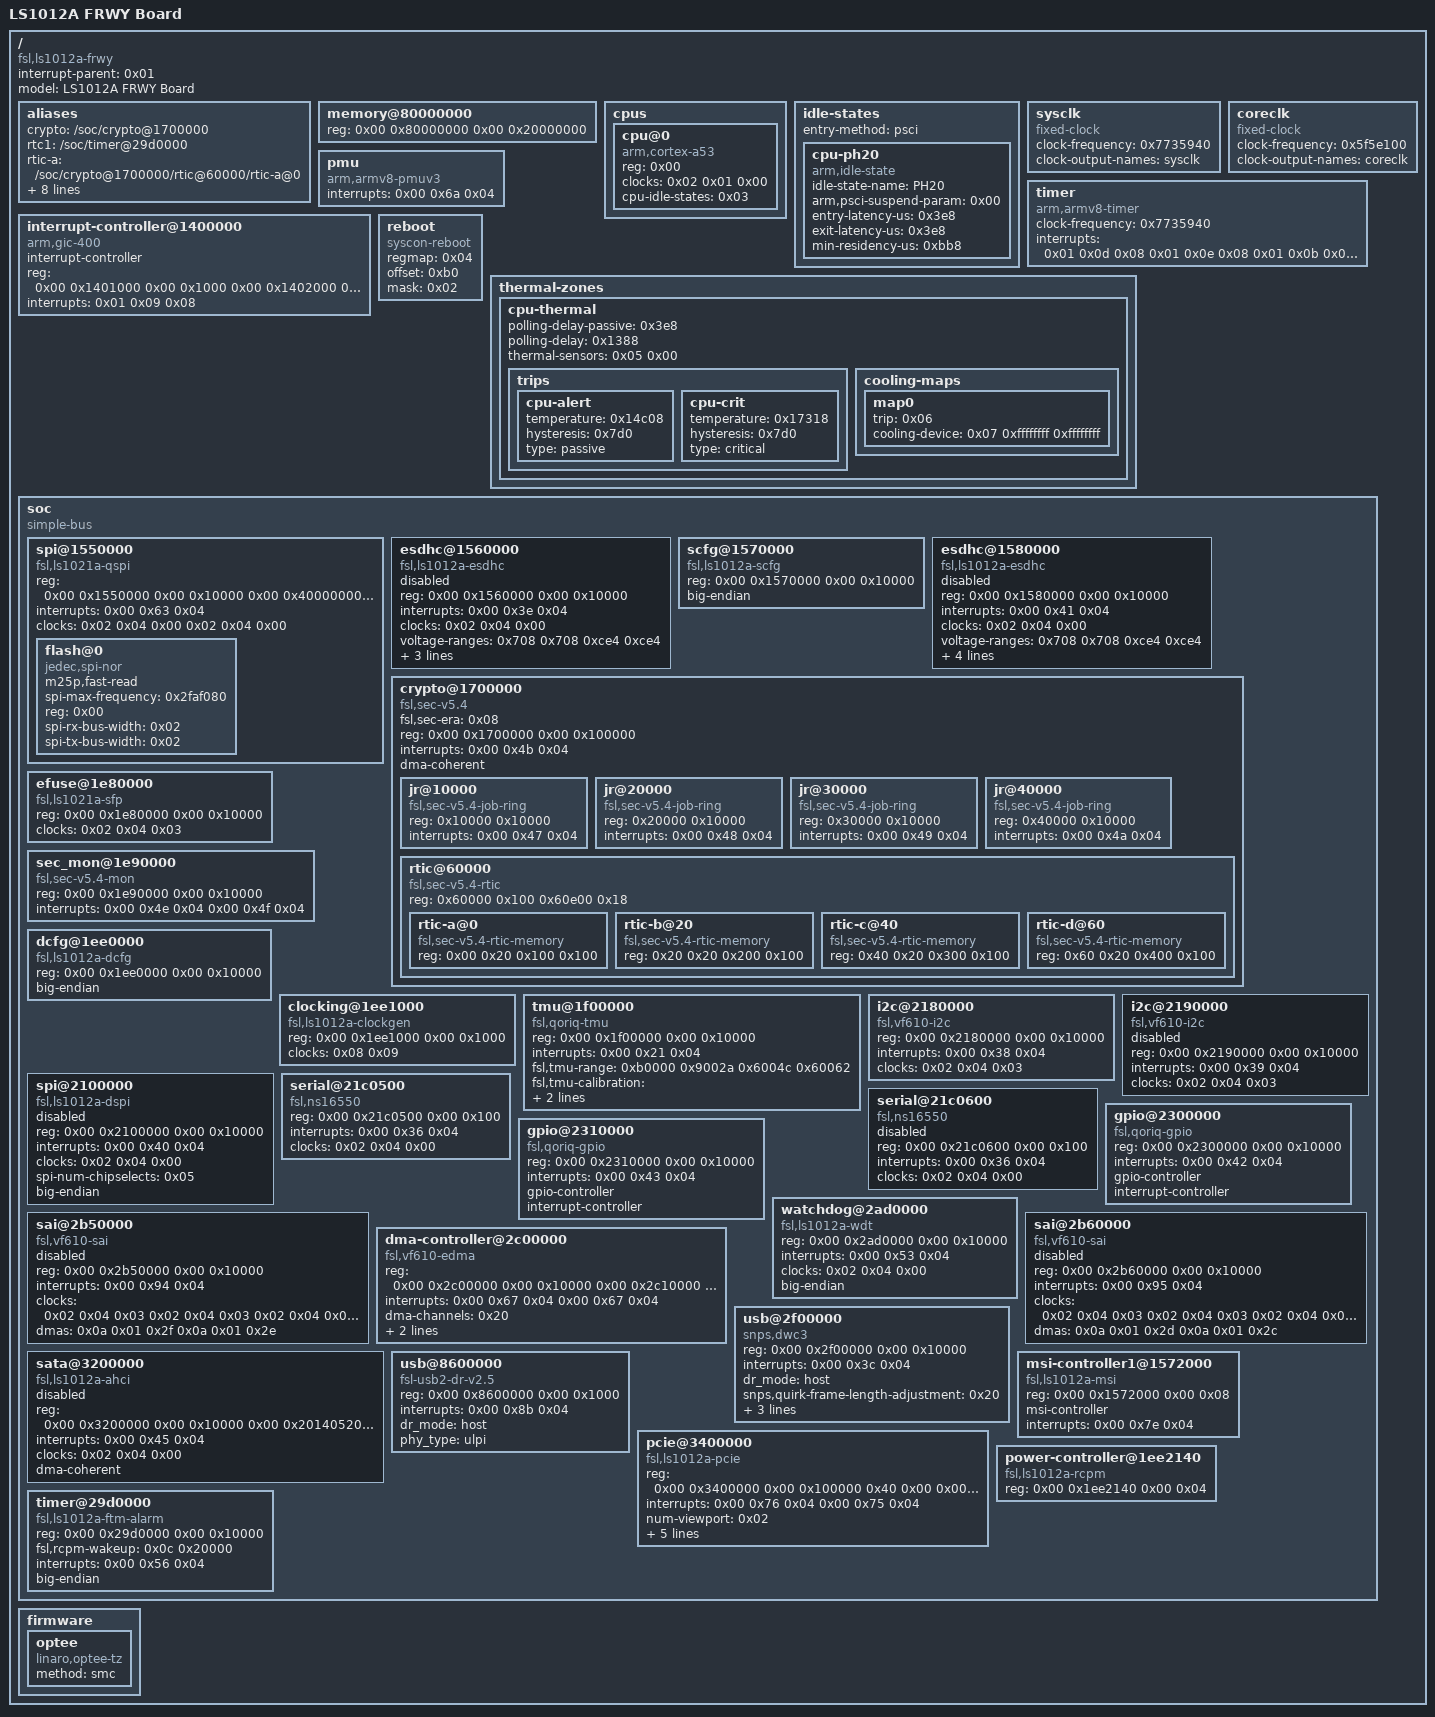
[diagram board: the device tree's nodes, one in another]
/*
 * Copyright Linux Kernel Team
 *
 * SPDX-License-Identifier: GPL-2.0-only
 *
 * This file is derived from an intermediate build stage of the
 * Linux kernel. The licenses of all input files to this process
 * are compatible with GPL-2.0-only.
 */

/dts-v1/;

/ {
	compatible = "fsl,ls1012a-frwy\0fsl,ls1012a";
	interrupt-parent = <0x01>;
	#address-cells = <0x02>;
	#size-cells = <0x02>;
	model = "LS1012A FRWY Board";

	aliases {
		crypto = "/soc/crypto@1700000";
		rtc1 = "/soc/timer@29d0000";
		rtic-a = "/soc/crypto@1700000/rtic@60000/rtic-a@0";
		rtic-b = "/soc/crypto@1700000/rtic@60000/rtic-b@20";
		rtic-c = "/soc/crypto@1700000/rtic@60000/rtic-c@40";
		rtic-d = "/soc/crypto@1700000/rtic@60000/rtic-d@60";
		sec-mon = "/soc/sec_mon@1e90000";
		serial0 = "/soc/serial@21c0500";
	};

	memory@80000000 {
		device_type = "memory";
		reg = < 0x00 0x80000000 0x00 0x20000000 >;
	};

	cpus {
		#address-cells = <0x01>;
		#size-cells = <0x00>;

		cpu@0 {
			device_type = "cpu";
			compatible = "arm,cortex-a53";
			reg = <0x00>;
			clocks = <0x02 0x01 0x00>;
			#cooling-cells = <0x02>;
			cpu-idle-states = <0x03>;
			phandle = <0x07>;
		};
	};

	idle-states {
		entry-method = "psci";

		cpu-ph20 {
			compatible = "arm,idle-state";
			idle-state-name = "PH20";
			arm,psci-suspend-param = <0x00>;
			entry-latency-us = <0x3e8>;
			exit-latency-us = <0x3e8>;
			min-residency-us = <0xbb8>;
			phandle = <0x03>;
		};
	};

	sysclk {
		compatible = "fixed-clock";
		#clock-cells = <0x00>;
		clock-frequency = <0x7735940>;
		clock-output-names = "sysclk";
		phandle = <0x08>;
	};

	coreclk {
		compatible = "fixed-clock";
		#clock-cells = <0x00>;
		clock-frequency = <0x5f5e100>;
		clock-output-names = "coreclk";
		phandle = <0x09>;
	};

	timer {
		compatible = "arm,armv8-timer";
		clock-frequency = <0x7735940>;
		interrupts = <0x01 0x0d 0x08 0x01 0x0e 0x08 0x01 0x0b 0x08 0x01 0x0a 0x08>;
	};

	pmu {
		compatible = "arm,armv8-pmuv3";
		interrupts = <0x00 0x6a 0x04>;
	};

	interrupt-controller@1400000 {
		compatible = "arm,gic-400";
		#interrupt-cells = <0x03>;
		interrupt-controller;
		reg = <0x00 0x1401000 0x00 0x1000 0x00 0x1402000 0x00 0x2000 0x00 0x1404000 0x00 0x2000 0x00 0x1406000 0x00 0x2000>;
		interrupts = <0x01 0x09 0x08>;
		phandle = <0x01>;
	};

	reboot {
		compatible = "syscon-reboot";
		regmap = <0x04>;
		offset = <0xb0>;
		mask = <0x02>;
	};

	thermal-zones {

		cpu-thermal {
			polling-delay-passive = <0x3e8>;
			polling-delay = <0x1388>;
			thermal-sensors = <0x05 0x00>;

			trips {

				cpu-alert {
					temperature = <0x14c08>;
					hysteresis = <0x7d0>;
					type = "passive";
					phandle = <0x06>;
				};

				cpu-crit {
					temperature = <0x17318>;
					hysteresis = <0x7d0>;
					type = "critical";
				};
			};

			cooling-maps {

				map0 {
					trip = <0x06>;
					cooling-device = <0x07 0xffffffff 0xffffffff>;
				};
			};
		};
	};

	soc {
		compatible = "simple-bus";
		#address-cells = <0x02>;
		#size-cells = <0x02>;
		ranges;

		spi@1550000 {
			compatible = "fsl,ls1021a-qspi";
			#address-cells = <0x01>;
			#size-cells = <0x00>;
			reg = <0x00 0x1550000 0x00 0x10000 0x00 0x40000000 0x00 0x10000000>;
			reg-names = "QuadSPI\0QuadSPI-memory";
			interrupts = <0x00 0x63 0x04>;
			clock-names = "qspi_en\0qspi";
			clocks = <0x02 0x04 0x00 0x02 0x04 0x00>;
			status = "okay";

			flash@0 {
				compatible = "jedec,spi-nor";
				#address-cells = <0x01>;
				#size-cells = <0x01>;
				m25p,fast-read;
				spi-max-frequency = <0x2faf080>;
				reg = <0x00>;
				spi-rx-bus-width = <0x02>;
				spi-tx-bus-width = <0x02>;
			};
		};

		esdhc@1560000 {
			compatible = "fsl,ls1012a-esdhc\0fsl,esdhc";
			reg = <0x00 0x1560000 0x00 0x10000>;
			interrupts = <0x00 0x3e 0x04>;
			clocks = <0x02 0x04 0x00>;
			voltage-ranges = <0x708 0x708 0xce4 0xce4>;
			sdhci,auto-cmd12;
			big-endian;
			bus-width = <0x04>;
			status = "disabled";
		};

		scfg@1570000 {
			compatible = "fsl,ls1012a-scfg\0syscon";
			reg = <0x00 0x1570000 0x00 0x10000>;
			big-endian;
		};

		esdhc@1580000 {
			compatible = "fsl,ls1012a-esdhc\0fsl,esdhc";
			reg = <0x00 0x1580000 0x00 0x10000>;
			interrupts = <0x00 0x41 0x04>;
			clocks = <0x02 0x04 0x00>;
			voltage-ranges = <0x708 0x708 0xce4 0xce4>;
			sdhci,auto-cmd12;
			big-endian;
			broken-cd;
			bus-width = <0x04>;
			status = "disabled";
		};

		crypto@1700000 {
			compatible = "fsl,sec-v5.4\0fsl,sec-v5.0\0fsl,sec-v4.0";
			fsl,sec-era = <0x08>;
			#address-cells = <0x01>;
			#size-cells = <0x01>;
			ranges = <0x00 0x00 0x1700000 0x100000>;
			reg = <0x00 0x1700000 0x00 0x100000>;
			interrupts = <0x00 0x4b 0x04>;
			dma-coherent;

			jr@10000 {
				compatible = "fsl,sec-v5.4-job-ring\0fsl,sec-v5.0-job-ring\0fsl,sec-v4.0-job-ring";
				reg = <0x10000 0x10000>;
				interrupts = <0x00 0x47 0x04>;
			};

			jr@20000 {
				compatible = "fsl,sec-v5.4-job-ring\0fsl,sec-v5.0-job-ring\0fsl,sec-v4.0-job-ring";
				reg = <0x20000 0x10000>;
				interrupts = <0x00 0x48 0x04>;
			};

			jr@30000 {
				compatible = "fsl,sec-v5.4-job-ring\0fsl,sec-v5.0-job-ring\0fsl,sec-v4.0-job-ring";
				reg = <0x30000 0x10000>;
				interrupts = <0x00 0x49 0x04>;
			};

			jr@40000 {
				compatible = "fsl,sec-v5.4-job-ring\0fsl,sec-v5.0-job-ring\0fsl,sec-v4.0-job-ring";
				reg = <0x40000 0x10000>;
				interrupts = <0x00 0x4a 0x04>;
			};

			rtic@60000 {
				compatible = "fsl,sec-v5.4-rtic\0fsl,sec-v5.0-rtic\0fsl,sec-v4.0-rtic";
				#address-cells = <0x01>;
				#size-cells = <0x01>;
				reg = <0x60000 0x100 0x60e00 0x18>;
				ranges = <0x00 0x60100 0x500>;

				rtic-a@0 {
					compatible = "fsl,sec-v5.4-rtic-memory\0fsl,sec-v5.0-rtic-memory\0fsl,sec-v4.0-rtic-memory";
					reg = <0x00 0x20 0x100 0x100>;
				};

				rtic-b@20 {
					compatible = "fsl,sec-v5.4-rtic-memory\0fsl,sec-v5.0-rtic-memory\0fsl,sec-v4.0-rtic-memory";
					reg = <0x20 0x20 0x200 0x100>;
				};

				rtic-c@40 {
					compatible = "fsl,sec-v5.4-rtic-memory\0fsl,sec-v5.0-rtic-memory\0fsl,sec-v4.0-rtic-memory";
					reg = <0x40 0x20 0x300 0x100>;
				};

				rtic-d@60 {
					compatible = "fsl,sec-v5.4-rtic-memory\0fsl,sec-v5.0-rtic-memory\0fsl,sec-v4.0-rtic-memory";
					reg = <0x60 0x20 0x400 0x100>;
				};
			};
		};

		efuse@1e80000 {
			compatible = "fsl,ls1021a-sfp";
			reg = <0x00 0x1e80000 0x00 0x10000>;
			clocks = <0x02 0x04 0x03>;
			clock-names = "sfp";
		};

		sec_mon@1e90000 {
			compatible = "fsl,sec-v5.4-mon\0fsl,sec-v5.0-mon\0fsl,sec-v4.0-mon";
			reg = <0x00 0x1e90000 0x00 0x10000>;
			interrupts = <0x00 0x4e 0x04 0x00 0x4f 0x04>;
		};

		dcfg@1ee0000 {
			compatible = "fsl,ls1012a-dcfg\0syscon";
			reg = <0x00 0x1ee0000 0x00 0x10000>;
			big-endian;
			phandle = <0x04>;
		};

		clocking@1ee1000 {
			compatible = "fsl,ls1012a-clockgen";
			reg = <0x00 0x1ee1000 0x00 0x1000>;
			#clock-cells = <0x02>;
			clocks = <0x08 0x09>;
			clock-names = "sysclk\0coreclk";
			phandle = <0x02>;
		};

		tmu@1f00000 {
			compatible = "fsl,qoriq-tmu";
			reg = <0x00 0x1f00000 0x00 0x10000>;
			interrupts = <0x00 0x21 0x04>;
			fsl,tmu-range = <0xb0000 0x9002a 0x6004c 0x60062>;
			fsl,tmu-calibration = <0x00 0x25 0x01 0x2c 0x02 0x32 0x03 0x39 0x04 0x3f 0x05 0x46 0x06 0x4c 0x07 0x53 0x08 0x59 0x09 0x5f 0x0a 0x66 0x0b 0x6c 0x10000 0x26 0x10001 0x2d 0x10002 0x35 0x10003 0x3d 0x10004 0x45 0x10005 0x4d 0x10006 0x55 0x10007 0x5d 0x10008 0x65 0x10009 0x6d 0x20000 0x26 0x20001 0x30 0x20002 0x3a 0x20003 0x44 0x20004 0x4e 0x20005 0x59 0x20006 0x63 0x30000 0x14 0x30001 0x21 0x30002 0x2e 0x30003 0x3a 0x30004 0x47 0x30005 0x53 0x30006 0x60>;
			big-endian;
			#thermal-sensor-cells = <0x01>;
			phandle = <0x05>;
		};

		i2c@2180000 {
			compatible = "fsl,vf610-i2c";
			#address-cells = <0x01>;
			#size-cells = <0x00>;
			reg = <0x00 0x2180000 0x00 0x10000>;
			interrupts = <0x00 0x38 0x04>;
			clocks = <0x02 0x04 0x03>;
			status = "okay";
		};

		i2c@2190000 {
			compatible = "fsl,vf610-i2c";
			#address-cells = <0x01>;
			#size-cells = <0x00>;
			reg = <0x00 0x2190000 0x00 0x10000>;
			interrupts = <0x00 0x39 0x04>;
			clocks = <0x02 0x04 0x03>;
			status = "disabled";
		};

		spi@2100000 {
			compatible = "fsl,ls1012a-dspi\0fsl,ls1021a-v1.0-dspi";
			#address-cells = <0x01>;
			#size-cells = <0x00>;
			reg = <0x00 0x2100000 0x00 0x10000>;
			interrupts = <0x00 0x40 0x04>;
			clock-names = "dspi";
			clocks = <0x02 0x04 0x00>;
			spi-num-chipselects = <0x05>;
			big-endian;
			status = "disabled";
		};

		serial@21c0500 {
			compatible = "fsl,ns16550\0ns16550a";
			reg = <0x00 0x21c0500 0x00 0x100>;
			interrupts = <0x00 0x36 0x04>;
			clocks = <0x02 0x04 0x00>;
			status = "okay";
		};

		serial@21c0600 {
			compatible = "fsl,ns16550\0ns16550a";
			reg = <0x00 0x21c0600 0x00 0x100>;
			interrupts = <0x00 0x36 0x04>;
			clocks = <0x02 0x04 0x00>;
			status = "disabled";
		};

		gpio@2300000 {
			compatible = "fsl,qoriq-gpio";
			reg = <0x00 0x2300000 0x00 0x10000>;
			interrupts = <0x00 0x42 0x04>;
			gpio-controller;
			#gpio-cells = <0x02>;
			interrupt-controller;
			#interrupt-cells = <0x02>;
		};

		gpio@2310000 {
			compatible = "fsl,qoriq-gpio";
			reg = <0x00 0x2310000 0x00 0x10000>;
			interrupts = <0x00 0x43 0x04>;
			gpio-controller;
			#gpio-cells = <0x02>;
			interrupt-controller;
			#interrupt-cells = <0x02>;
		};

		watchdog@2ad0000 {
			compatible = "fsl,ls1012a-wdt\0fsl,imx21-wdt";
			reg = <0x00 0x2ad0000 0x00 0x10000>;
			interrupts = <0x00 0x53 0x04>;
			clocks = <0x02 0x04 0x00>;
			big-endian;
		};

		sai@2b50000 {
			#sound-dai-cells = <0x00>;
			compatible = "fsl,vf610-sai";
			reg = <0x00 0x2b50000 0x00 0x10000>;
			interrupts = <0x00 0x94 0x04>;
			clocks = <0x02 0x04 0x03 0x02 0x04 0x03 0x02 0x04 0x03 0x02 0x04 0x03>;
			clock-names = "bus\0mclk1\0mclk2\0mclk3";
			dma-names = "tx\0rx";
			dmas = <0x0a 0x01 0x2f 0x0a 0x01 0x2e>;
			status = "disabled";
		};

		sai@2b60000 {
			#sound-dai-cells = <0x00>;
			compatible = "fsl,vf610-sai";
			reg = <0x00 0x2b60000 0x00 0x10000>;
			interrupts = <0x00 0x95 0x04>;
			clocks = <0x02 0x04 0x03 0x02 0x04 0x03 0x02 0x04 0x03 0x02 0x04 0x03>;
			clock-names = "bus\0mclk1\0mclk2\0mclk3";
			dma-names = "tx\0rx";
			dmas = <0x0a 0x01 0x2d 0x0a 0x01 0x2c>;
			status = "disabled";
		};

		dma-controller@2c00000 {
			#dma-cells = <0x02>;
			compatible = "fsl,vf610-edma";
			reg = <0x00 0x2c00000 0x00 0x10000 0x00 0x2c10000 0x00 0x10000 0x00 0x2c20000 0x00 0x10000>;
			interrupts = <0x00 0x67 0x04 0x00 0x67 0x04>;
			interrupt-names = "edma-tx\0edma-err";
			dma-channels = <0x20>;
			big-endian;
			clock-names = "dmamux0\0dmamux1";
			clocks = <0x02 0x04 0x03 0x02 0x04 0x03>;
			phandle = <0x0a>;
		};

		usb@2f00000 {
			compatible = "snps,dwc3";
			reg = <0x00 0x2f00000 0x00 0x10000>;
			interrupts = <0x00 0x3c 0x04>;
			dr_mode = "host";
			snps,quirk-frame-length-adjustment = <0x20>;
			snps,dis_rxdet_inp3_quirk;
			snps,incr-burst-type-adjustment = <0x01 0x04 0x08 0x10>;
		};

		sata@3200000 {
			compatible = "fsl,ls1012a-ahci\0fsl,ls1043a-ahci";
			reg = <0x00 0x3200000 0x00 0x10000 0x00 0x20140520 0x00 0x04>;
			reg-names = "ahci\0sata-ecc";
			interrupts = <0x00 0x45 0x04>;
			clocks = <0x02 0x04 0x00>;
			dma-coherent;
			status = "disabled";
		};

		usb@8600000 {
			compatible = "fsl-usb2-dr-v2.5\0fsl-usb2-dr";
			reg = <0x00 0x8600000 0x00 0x1000>;
			interrupts = <0x00 0x8b 0x04>;
			dr_mode = "host";
			phy_type = "ulpi";
		};

		msi-controller1@1572000 {
			compatible = "fsl,ls1012a-msi";
			reg = <0x00 0x1572000 0x00 0x08>;
			msi-controller;
			interrupts = <0x00 0x7e 0x04>;
			phandle = <0x0b>;
		};

		pcie@3400000 {
			compatible = "fsl,ls1012a-pcie";
			reg = <0x00 0x3400000 0x00 0x100000 0x40 0x00 0x00 0x2000>;
			reg-names = "regs\0config";
			interrupts = <0x00 0x76 0x04 0x00 0x75 0x04>;
			interrupt-names = "aer\0pme";
			#address-cells = <0x03>;
			#size-cells = <0x02>;
			device_type = "pci";
			num-viewport = <0x02>;
			bus-range = <0x00 0xff>;
			ranges = <0x81000000 0x00 0x00 0x40 0x10000 0x00 0x10000 0x82000000 0x00 0x40000000 0x40 0x40000000 0x00 0x40000000>;
			msi-parent = <0x0b>;
			#interrupt-cells = <0x01>;
			interrupt-map-mask = <0x00 0x00 0x00 0x07>;
			interrupt-map = <0x00 0x00 0x00 0x01 0x01 0x00 0x6e 0x04 0x00 0x00 0x00 0x02 0x01 0x00 0x6f 0x04 0x00 0x00 0x00 0x03 0x01 0x00 0x70 0x04 0x00 0x00 0x00 0x04 0x01 0x00 0x71 0x04>;
			status = "okay";
		};

		power-controller@1ee2140 {
			compatible = "fsl,ls1012a-rcpm\0fsl,qoriq-rcpm-2.1+";
			reg = <0x00 0x1ee2140 0x00 0x04>;
			#fsl,rcpm-wakeup-cells = <0x01>;
			phandle = <0x0c>;
		};

		timer@29d0000 {
			compatible = "fsl,ls1012a-ftm-alarm";
			reg = <0x00 0x29d0000 0x00 0x10000>;
			fsl,rcpm-wakeup = <0x0c 0x20000>;
			interrupts = <0x00 0x56 0x04>;
			big-endian;
		};
	};

	firmware {

		optee {
			compatible = "linaro,optee-tz";
			method = "smc";
		};
	};
};
